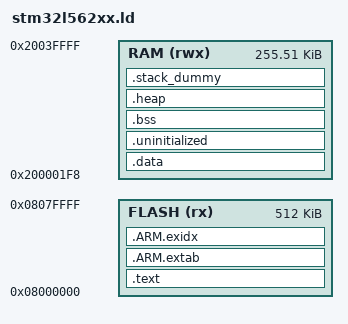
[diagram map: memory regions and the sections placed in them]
/* Linker script to configure memory regions. */
/*
 * SPDX-License-Identifier: BSD-3-Clause
 ******************************************************************************
 * @attention
 *
 * Copyright (c) 2016-2020 STMicroelectronics.
 * All rights reserved.
 *
 * This software component is licensed by ST under BSD 3-Clause license,
 * the "License"; You may not use this file except in compliance with the
 * License. You may obtain a copy of the License at:
 *                        opensource.org/licenses/BSD-3-Clause
 *
 ******************************************************************************
*/

/* vectsise is ((125 * 4) + 7) & 0xFFFFFFF8) = 0x1F8

   Vects at start of RAM(?) - so add offset*/

_Min_Stack_Size = 0x400;
MEMORY
{
    FLASH (rx)   : ORIGIN = 0x8000000, LENGTH = 0x80000
    RAM (rwx)    : ORIGIN = 0x200001F8, LENGTH = 0x3FE08
}

/* Linker script to place sections and symbol values. Should be used together
 * with other linker script that defines memory regions FLASH and RAM.
 * It references following symbols, which must be defined in code:
 *   Reset_Handler : Entry of reset handler
 *
 * It defines following symbols, which code can use without definition:
 *   __exidx_start
 *   __exidx_end
 *   __etext
 *   __data_start__
 *   __preinit_array_start
 *   __preinit_array_end
 *   __init_array_start
 *   __init_array_end
 *   __fini_array_start
 *   __fini_array_end
 *   __data_end__
 *   __bss_start__
 *   __bss_end__
 *   __end__
 *   end
 *   __HeapLimit
 *   __StackLimit
 *   __StackTop
 *   __stack
 *   _estack
 */
ENTRY(Reset_Handler)

SECTIONS
{
    .text :
    {
        KEEP(*(.isr_vector))
        *(.text*)

        KEEP(*(.init))
        KEEP(*(.fini))

        /* .ctors */
        *crtbegin.o(.ctors)
        *crtbegin?.o(.ctors)
        *(EXCLUDE_FILE(*crtend?.o *crtend.o) .ctors)
        *(SORT(.ctors.*))
        *(.ctors)

        /* .dtors */
        *crtbegin.o(.dtors)
        *crtbegin?.o(.dtors)
        *(EXCLUDE_FILE(*crtend?.o *crtend.o) .dtors)
        *(SORT(.dtors.*))
        *(.dtors)

        *(.rodata*)

        KEEP(*(.eh_frame*))
    } > FLASH

    .ARM.extab :
    {
        *(.ARM.extab* .gnu.linkonce.armextab.*)
    } > FLASH

    __exidx_start = .;
    .ARM.exidx :
    {
        *(.ARM.exidx* .gnu.linkonce.armexidx.*)
    } > FLASH
    __exidx_end = .;

    /* Location counter can end up 2byte aligned with narrow Thumb code but
       __etext is assumed by startup code to be the LMA of a section in RAM
       which must be 8-byte aligned */
    __etext = ALIGN (8);
    _sidata = .;
    
    .data : AT (__etext)
    {
        __data_start__ = .;
        _sdata = .;
        *(vtable)
        *(.data*)

        . = ALIGN(4);
        /* preinit data */
        PROVIDE_HIDDEN (__preinit_array_start = .);
        KEEP(*(.preinit_array))
        PROVIDE_HIDDEN (__preinit_array_end = .);

        . = ALIGN(4);
        /* init data */
        PROVIDE_HIDDEN (__init_array_start = .);
        KEEP(*(SORT(.init_array.*)))
        KEEP(*(.init_array))
        PROVIDE_HIDDEN (__init_array_end = .);

        . = ALIGN(4);
        /* finit data */
        PROVIDE_HIDDEN (__fini_array_start = .);
        KEEP(*(SORT(.fini_array.*)))
        KEEP(*(.fini_array))
        PROVIDE_HIDDEN (__fini_array_end = .);

        KEEP(*(.jcr*))
        . = ALIGN(4);
        /* All data end */
        __data_end__ = .;
        _edata = .;

    } > RAM

    /* Uninitialized data section
     * This region is not initialized by the C/C++ library and can be used to
     * store state across soft reboots. */
    .uninitialized (NOLOAD):
    {
        . = ALIGN(32);
        __uninitialized_start = .;
        *(.uninitialized)
        KEEP(*(.keep.uninitialized))
        . = ALIGN(32);
        __uninitialized_end = .;
    } > RAM
    
    .bss :
    {
        . = ALIGN(4);
        __bss_start__ = .;
        _sbss = .;
        *(.bss*)
        *(COMMON)
        . = ALIGN(4);
        __bss_end__ = .;
        _ebss = .;
    } > RAM

    .heap (COPY):
    {
        __end__ = .;
        PROVIDE(end = .);
        *(.heap*)
        . = ORIGIN(RAM) + LENGTH(RAM) - 0x1000; /*0x1000 = MBED_BOOT_STACK_SIZE */
        __HeapLimit = .;
    } > RAM

    /* .stack_dummy section doesn't contains any symbols. It is only
     * used for linker to calculate size of stack sections, and assign
     * values to stack symbols later */
    .stack_dummy (COPY):
    {
        *(.stack*)
    } > RAM

    /* Set stack top to end of RAM, and stack limit move down by
     * size of stack_dummy section */
    __StackTop = ORIGIN(RAM) + LENGTH(RAM);
    _estack = __StackTop;
    __StackLimit = __StackTop - 0x1000; /*0x1000 = MBED_BOOT_STACK_SIZE */
    PROVIDE(__stack = __StackTop);

    /* Check if data + heap + stack exceeds RAM limit */
    ASSERT(__StackLimit >= __HeapLimit, "region RAM overflowed with stack")
}
